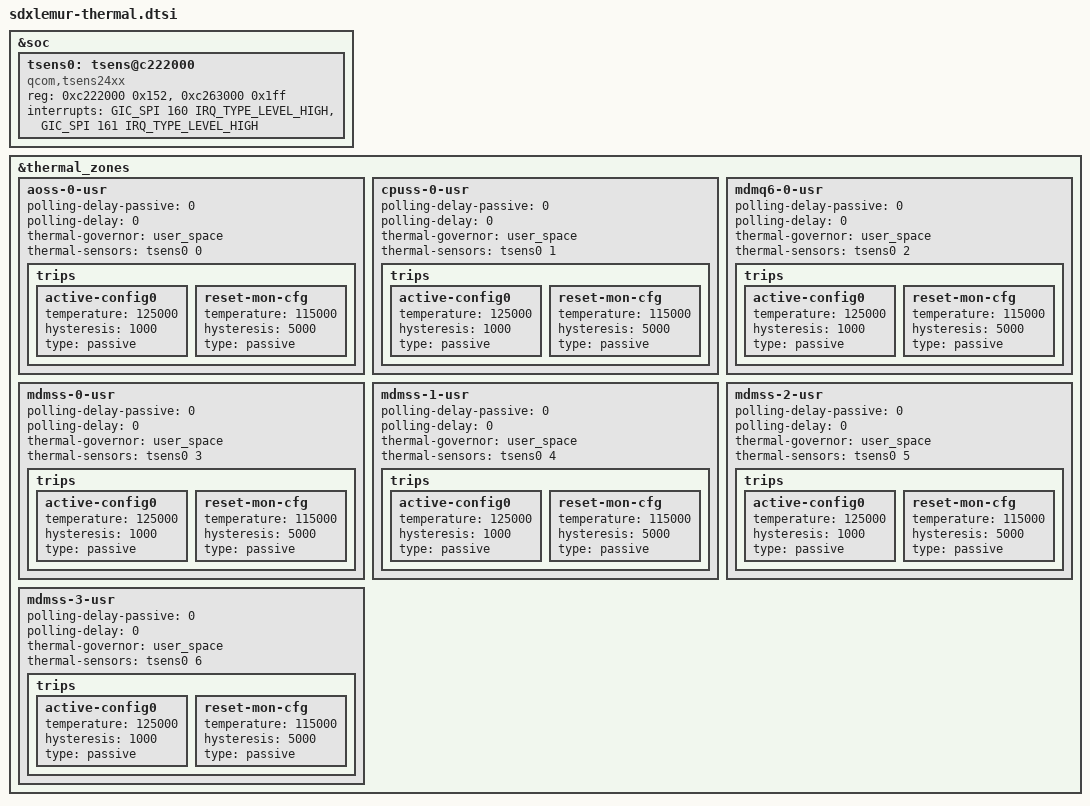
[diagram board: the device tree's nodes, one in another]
&soc {
	tsens0: tsens@c222000 {
		compatible = "qcom,tsens24xx";
		reg = <0xc222000 0x152>,
			<0xc263000 0x1ff>;
		reg-names = "tsens_srot_physical",
				"tsens_tm_physical";
		interrupts = <GIC_SPI 160 IRQ_TYPE_LEVEL_HIGH>,
				<GIC_SPI 161 IRQ_TYPE_LEVEL_HIGH>;
		interrupt-names = "tsens-upper-lower", "tsens-critical";
		#thermal-sensor-cells = <1>;
	};
};

&thermal_zones {
	aoss-0-usr {
		polling-delay-passive = <0>;
		polling-delay = <0>;
		thermal-governor = "user_space";
		thermal-sensors = <&tsens0 0>;
		trips {
			active-config0 {
				temperature = <125000>;
				hysteresis = <1000>;
				type = "passive";
			};

			reset-mon-cfg {
				temperature = <115000>;
				hysteresis = <5000>;
				type = "passive";
			};
		};
	};

	cpuss-0-usr {
		polling-delay-passive = <0>;
		polling-delay = <0>;
		thermal-governor = "user_space";
		thermal-sensors = <&tsens0 1>;
		trips {
			active-config0 {
				temperature = <125000>;
				hysteresis = <1000>;
				type = "passive";
			};

			reset-mon-cfg {
				temperature = <115000>;
				hysteresis = <5000>;
				type = "passive";
			};
		};
	};

	mdmq6-0-usr {
		polling-delay-passive = <0>;
		polling-delay = <0>;
		thermal-governor = "user_space";
		thermal-sensors = <&tsens0 2>;
		trips {
			active-config0 {
				temperature = <125000>;
				hysteresis = <1000>;
				type = "passive";
			};

			reset-mon-cfg {
				temperature = <115000>;
				hysteresis = <5000>;
				type = "passive";
			};
		};
	};

	mdmss-0-usr {
		polling-delay-passive = <0>;
		polling-delay = <0>;
		thermal-governor = "user_space";
		thermal-sensors = <&tsens0 3>;
		trips {
			active-config0 {
				temperature = <125000>;
				hysteresis = <1000>;
				type = "passive";
			};

			reset-mon-cfg {
				temperature = <115000>;
				hysteresis = <5000>;
				type = "passive";
			};
		};
	};

	mdmss-1-usr {
		polling-delay-passive = <0>;
		polling-delay = <0>;
		thermal-governor = "user_space";
		thermal-sensors = <&tsens0 4>;
		trips {
			active-config0 {
				temperature = <125000>;
				hysteresis = <1000>;
				type = "passive";
			};

			reset-mon-cfg {
				temperature = <115000>;
				hysteresis = <5000>;
				type = "passive";
			};
		};
	};

	mdmss-2-usr {
		polling-delay-passive = <0>;
		polling-delay = <0>;
		thermal-governor = "user_space";
		thermal-sensors = <&tsens0 5>;
		trips {
			active-config0 {
				temperature = <125000>;
				hysteresis = <1000>;
				type = "passive";
			};

			reset-mon-cfg {
				temperature = <115000>;
				hysteresis = <5000>;
				type = "passive";
			};
		};
	};

	mdmss-3-usr {
		polling-delay-passive = <0>;
		polling-delay = <0>;
		thermal-governor = "user_space";
		thermal-sensors = <&tsens0 6>;
		trips {
			active-config0 {
				temperature = <125000>;
				hysteresis = <1000>;
				type = "passive";
			};

			reset-mon-cfg {
				temperature = <115000>;
				hysteresis = <5000>;
				type = "passive";
			};
		};
	};
};
